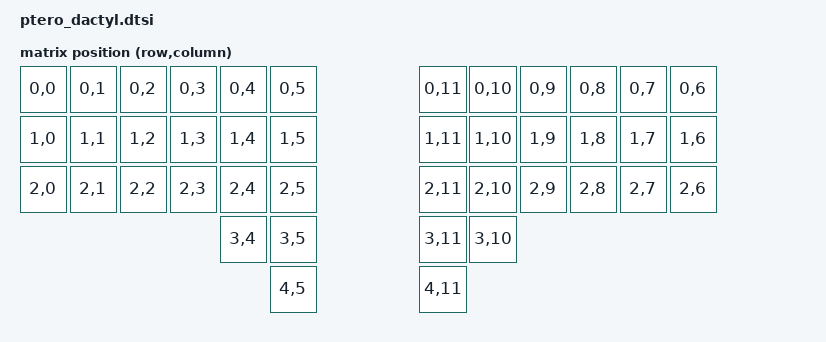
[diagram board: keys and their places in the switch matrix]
// This file was generated from a template. Edit it to match your keyboard.
// See https://zmk.dev/docs/development/hardware-integration/new-shield for more
// instructions.

#include <dt-bindings/zmk/matrix_transform.h>

// #include "ptero_dactyl-layouts.dtsi"

/ {
    chosen {
        zmk,kscan = &kscan0;
        zmk,matrix_transform = &default_transform;
    };

    default_transform: keymap_transform_0 {
        compatible = "zmk,matrix-transform";
        columns = <12>;
        rows = <5>;
        
	map = <
RC(0,0) RC(0,1) RC(0,2) RC(0,3) RC(0,4) RC(0,5)                   RC(0,11) RC(0,10) RC(0,9) RC(0,8) RC(0,7) RC(0,6)
RC(1,0) RC(1,1) RC(1,2) RC(1,3) RC(1,4) RC(1,5)                   RC(1,11) RC(1,10) RC(1,9) RC(1,8) RC(1,7) RC(1,6)
RC(2,0) RC(2,1) RC(2,2) RC(2,3) RC(2,4) RC(2,5)                   RC(2,11) RC(2,10) RC(2,9) RC(2,8) RC(2,7) RC(2,6)                                              
                                RC(3,4) RC(3,5)                   RC(3,11) RC(3,10)
                                        RC(4,5)                   RC(4,11)
        >;
    };

// Travis added A 1 row below, and made it the equals rather than comma. 

    kscan0: kscan {
        compatible = "zmk,kscan-gpio-matrix";
        label = "KSCAN";
        wakeup-source;

        diode-direction = "col2row";
    };
};

#include <dt-bindings/zmk/input_transform.h>
#include <zephyr/dt-bindings/input/input-event-codes.h>
#include <input/processors.dtsi>
#include <input/processors/zmk-input-processor-keybind.dtsi>
#include <input/processors/sensor_rotation.dtsi>

/ {
    /omit-if-no-ref/ zip_keybind_arrows: zip_keybind_arrows {
        compatible = "zmk,input-processor-keybind";
        #input-processor-cells = <0>;
        bindings = <&kp LEFT>,
                  <&kp RIGHT>,
                  <&kp DOWN>,
                  <&kp UP>;
        tick = <40>;
        wait-ms = <0>;
        tap-ms = <10>;
        threshold = <2>;
        mode = <1>;
    };

    /omit-if-no-ref/ zip_keybind_arrows_8w: zip_keybind_arrows_8w {
        compatible = "zmk,input-processor-keybind";
        #input-processor-cells = <0>;
        bindings = <&kp LEFT>,
                  <&kp RIGHT>,
                  <&kp DOWN>,
                  <&kp UP>;
        tick = <40>;
        wait-ms = <0>;
        tap-ms = <10>;
        threshold = <2>;
        mode = <2>;
    };

    /omit-if-no-ref/ central_sensor_rotation: central_sensor_rotation {
        compatible = "zmk,input-processor-sensor-rotation";
        #input-processor-cells = <0>;
        rotation-angle = <18>;
    };

    /omit-if-no-ref/ peripheral_sensor_rotation: peripheral_sensor_rotation {
        compatible = "zmk,input-processor-sensor-rotation";
        #input-processor-cells = <0>;
        rotation-angle = <18>;
    };

};


/ {
    split_inputs {
        #address-cells = <1>;
        #size-cells = <0>;

        trackball_split: trackball_split@0 {
            compatible = "zmk,input-split";
            reg = <0>;
        };
    };

    trackball_listener: trackball_listener {
        compatible = "zmk,input-listener";
        status = "disabled";
        device = <&trackball_split>;

        input-processors = <&central_sensor_rotation>;

        scroll {
            layers = <1 2 3>;
            input-processors = <&zip_xy_transform (INPUT_TRANSFORM_X_INVERT | INPUT_TRANSFORM_Y_INVERT)>, <&zip_xy_scaler 1 16>, <&zip_xy_to_scroll_mapper>;
        };

        precise {
            layers = <5>;
            input-processors = <&zip_xy_scaler 1 8>;
            process-next;
        };

        arrows4 {
            layers = <4>;
            input-processors = <&central_sensor_rotation>, <&zip_keybind_arrows>;
        };

        arrows8 {
            layers = <6>;
            input-processors = <&central_sensor_rotation>, <&zip_keybind_arrows_8w>;
        };
    };

    trackball_central_listener: trackball_central_listener {
        compatible = "zmk,input-listener";
        status = "disabled";
    };
};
